AUTOSAR XML (schema 4.0)
package /LEDStatusComponent
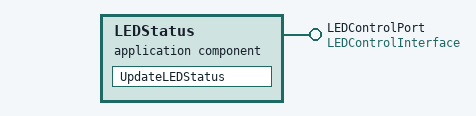
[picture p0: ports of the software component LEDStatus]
  application software component type LEDStatus
    provide port LEDControlPort: required-interface=LEDControlInterface
    internal behavior LEDStatusBehavior
      runnable UpdateLEDStatus
